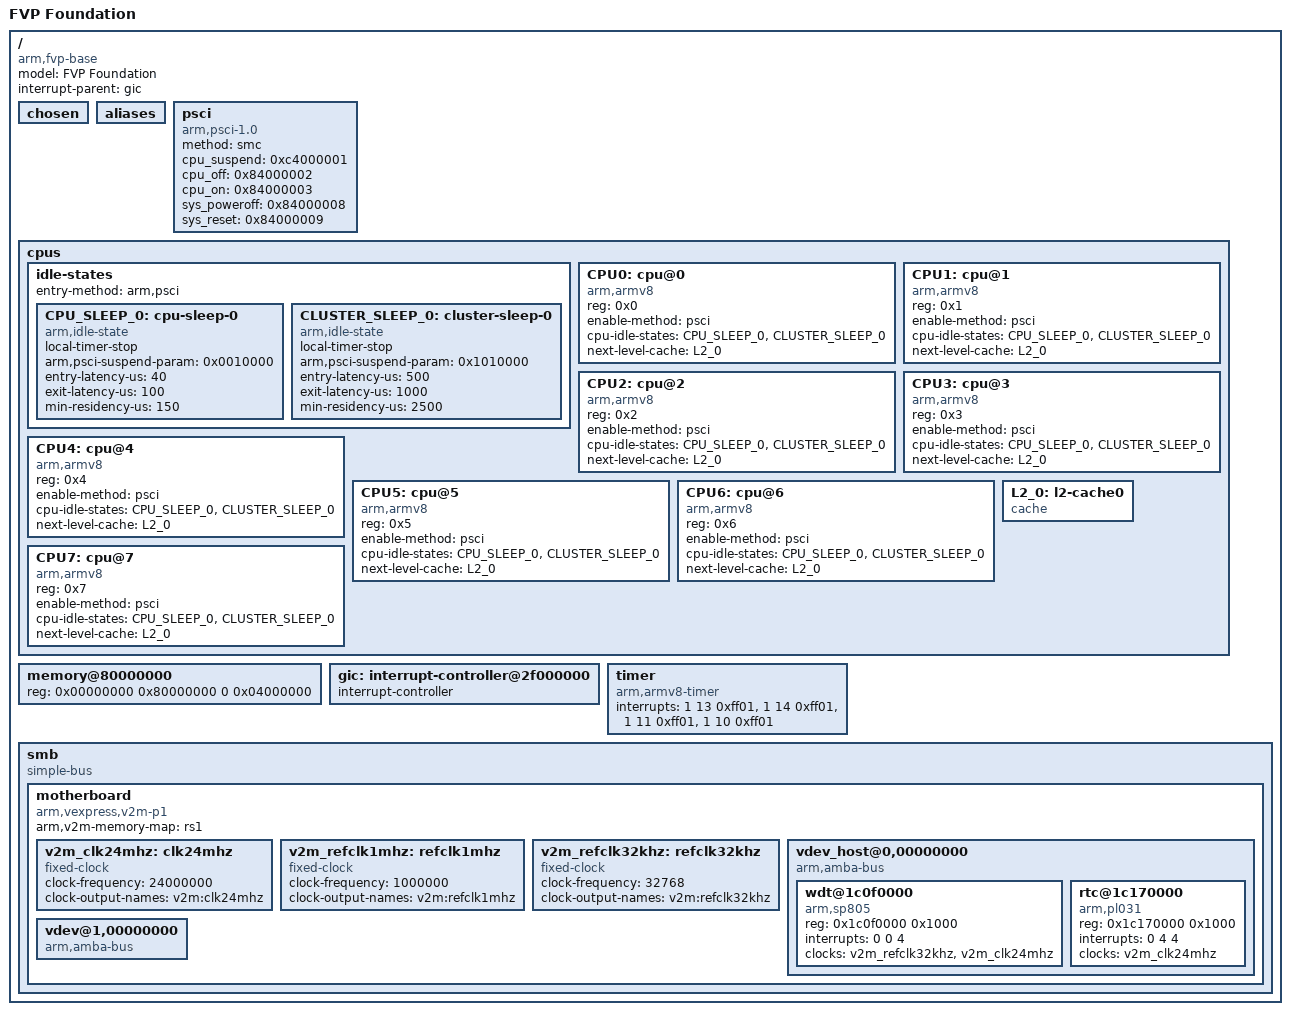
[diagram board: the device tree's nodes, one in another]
/*
 * Copyright (c) 2013-2017, ARM Limited and Contributors. All rights reserved.
 *
 * SPDX-License-Identifier: BSD-3-Clause
 */

/dts-v1/;

/memreserve/ 0x80000000 0x00010000;

/ {
};

/ {
	model = "FVP Foundation";
	compatible = "arm,fvp-base", "arm,vexpress";
	interrupt-parent = <&gic>;
	#address-cells = <2>;
	#size-cells = <2>;

	chosen {
	};

	aliases {
		/* serial0 = &v2m_serial0; */
	};

	psci {
		compatible = "arm,psci-1.0", "arm,psci-0.2", "arm,psci";
		method = "smc";
		cpu_suspend = <0xc4000001>;
		cpu_off = <0x84000002>;
		cpu_on = <0x84000003>;
		sys_poweroff = <0x84000008>;
		sys_reset = <0x84000009>;
	};

	cpus {
		#address-cells = <1>;
		#size-cells = <0>;

		idle-states {
			entry-method = "arm,psci";

			CPU_SLEEP_0: cpu-sleep-0 {
				compatible = "arm,idle-state";
				local-timer-stop;
				arm,psci-suspend-param = <0x0010000>;
				entry-latency-us = <40>;
				exit-latency-us = <100>;
				min-residency-us = <150>;
			};

			CLUSTER_SLEEP_0: cluster-sleep-0 {
				compatible = "arm,idle-state";
				local-timer-stop;
				arm,psci-suspend-param = <0x1010000>;
				entry-latency-us = <500>;
				exit-latency-us = <1000>;
				min-residency-us = <2500>;
			};
		};

		CPU0:cpu@0 {
			device_type = "cpu";
			compatible = "arm,armv8";
			reg = <0x0>;
			enable-method = "psci";
			cpu-idle-states = <&CPU_SLEEP_0 &CLUSTER_SLEEP_0>;
			next-level-cache = <&L2_0>;
		};

		CPU1:cpu@1 {
			device_type = "cpu";
			compatible = "arm,armv8";
			reg = <0x1>;
			enable-method = "psci";
			cpu-idle-states = <&CPU_SLEEP_0 &CLUSTER_SLEEP_0>;
			next-level-cache = <&L2_0>;
		};

		CPU2:cpu@2 {
			device_type = "cpu";
			compatible = "arm,armv8";
			reg = <0x2>;
			enable-method = "psci";
			cpu-idle-states = <&CPU_SLEEP_0 &CLUSTER_SLEEP_0>;
			next-level-cache = <&L2_0>;
		};

		CPU3:cpu@3 {
			device_type = "cpu";
			compatible = "arm,armv8";
			reg = <0x3>;
			enable-method = "psci";
			cpu-idle-states = <&CPU_SLEEP_0 &CLUSTER_SLEEP_0>;
			next-level-cache = <&L2_0>;
		};

		CPU4:cpu@4 {
			device_type = "cpu";
			compatible = "arm,armv8";
			reg = <0x4>;
			enable-method = "psci";
			cpu-idle-states = <&CPU_SLEEP_0 &CLUSTER_SLEEP_0>;
			next-level-cache = <&L2_0>;
		};

		CPU5:cpu@5 {
			device_type = "cpu";
			compatible = "arm,armv8";
			reg = <0x5>;
			enable-method = "psci";
			cpu-idle-states = <&CPU_SLEEP_0 &CLUSTER_SLEEP_0>;
			next-level-cache = <&L2_0>;
		};

		CPU6:cpu@6 {
			device_type = "cpu";
			compatible = "arm,armv8";
			reg = <0x6>;
			enable-method = "psci";
			cpu-idle-states = <&CPU_SLEEP_0 &CLUSTER_SLEEP_0>;
			next-level-cache = <&L2_0>;
		};

		CPU7:cpu@7 {
			device_type = "cpu";
			compatible = "arm,armv8";
			reg = <0x7>;
			enable-method = "psci";
			cpu-idle-states = <&CPU_SLEEP_0 &CLUSTER_SLEEP_0>;
			next-level-cache = <&L2_0>;
		};

		L2_0: l2-cache0 {
			compatible = "cache";
		};
	};

	memory@80000000 {
		device_type = "memory";
		reg = <0x00000000 0x80000000 0 0x04000000>;
	};

	gic: interrupt-controller@2f000000 {
		#interrupt-cells = <3>;
		#address-cells = <2>;
		#size-cells = <2>;
		ranges;
		interrupt-controller;
	};

	timer {
		compatible = "arm,armv8-timer";
		interrupts = <1 13 0xff01>,
			     <1 14 0xff01>,
			     <1 11 0xff01>,
			     <1 10 0xff01>;
	};

	smb {
		compatible = "simple-bus";

		#address-cells = <2>;
		#size-cells = <1>;
		ranges = <0 0 0 0x00000000 0x40000000>,
			 <1 0 0 0x40000000 0x40000000>;

		motherboard {
			arm,v2m-memory-map = "rs1";
			compatible = "arm,vexpress,v2m-p1", "simple-bus";
			#address-cells = <2>; /* SMB chipselect number and offset */
			#size-cells = <1>;
			ranges;

			v2m_clk24mhz: clk24mhz {
				compatible = "fixed-clock";
				#clock-cells = <0>;
				clock-frequency = <24000000>;
				clock-output-names = "v2m:clk24mhz";
			};

			v2m_refclk1mhz: refclk1mhz {
				compatible = "fixed-clock";
				#clock-cells = <0>;
				clock-frequency = <1000000>;
				clock-output-names = "v2m:refclk1mhz";
			};

			v2m_refclk32khz: refclk32khz {
				compatible = "fixed-clock";
				#clock-cells = <0>;
				clock-frequency = <32768>;
				clock-output-names = "v2m:refclk32khz";
			};

			vdev_host@0,00000000 {
				compatible = "arm,amba-bus", "simple-bus";
				#address-cells = <1>;
				#size-cells = <1>;
				ranges = <0 0 0 0x40000000>;

				wdt@1c0f0000 {
					compatible = "arm,sp805", "arm,primecell";
					reg = <0x1c0f0000 0x1000>;
					interrupts = <0 0 4>;
					clocks = <&v2m_refclk32khz>, <&v2m_clk24mhz>;
					clock-names = "wdogclk", "apb_pclk";
				};

				rtc@1c170000 {
					compatible = "arm,pl031", "arm,primecell";
					reg = <0x1c170000 0x1000>;
					interrupts = <0 4 4>;
					clocks = <&v2m_clk24mhz>;
					clock-names = "apb_pclk";
				};
			};

			vdev@1,00000000 {
				compatible = "arm,amba-bus", "simple-bus";
				#address-cells = <1>;
				#size-cells = <1>;
				ranges = <0 1 0 0x40000000>;
			};
		};
	};
};
